# GD32F1x0 register map
File version: 1.0
CPU: CM3 r2p1, little endian, no MPU, no FPU, 4 interrupt priority bits
Registers are 32-bit, read-write, reset 0x0 unless marked. A register's access mark holds for its fields unless they carry their own. Offsets are from the block's base; [hi:lo] are bit positions; {n}, {i} and the like mark numbered series.

## I2C0 — Inter integrated circuit
Base 0x40005400
Same registers: I2C1 0x40005800, I2C2 0x4000C000
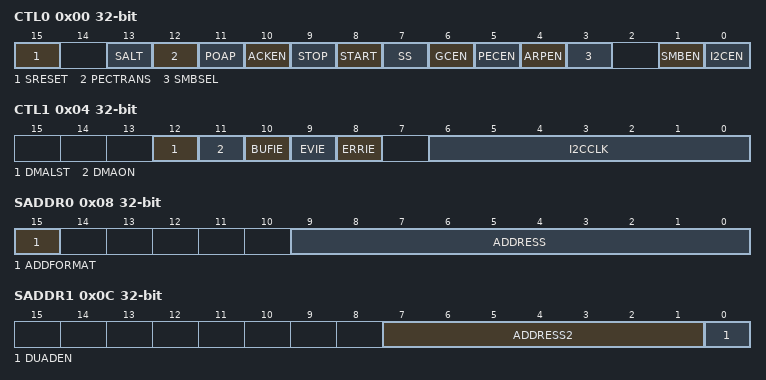
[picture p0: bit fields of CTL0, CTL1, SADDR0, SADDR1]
0x00 CTL0 — Control register 0
  [15] SRESET — Software reset I2C
  [13] SALT — SMBus alert
  [12] PECTRANS — PEC Transfer
  [11] POAP — Position of ACK meaning
  [10] ACKEN — Whether or not to send an ACK
  [9] STOP — Generate a STOP condition on I2C bus
  [8] START — Generate a START condition on I2C bus
  [7] SS — Whether to stretch SCL low when data is not ready in slave mode
  [6] GCEN — Whether or not to response to a General Call (0x00)
  [5] PECEN — PEC Calculation Switch
  [4] ARPEN — ARP protocol in SMBus switch
  [3] SMBSEL — SMBusType Selection
  [1] SMBEN — SMBus/I2C mode switch
  [0] I2CEN — I2C peripheral enable
0x04 CTL1 — Control register 1
  [12] DMALST — Flag indicating DMA last transfer
  [11] DMAON — DMA mode switch
  [10] BUFIE — Buffer interrupt enable
  [9] EVIE — Event interrupt enable
  [8] ERRIE — Error interrupt enable
  [6:0] I2CCLK — I2C Peripheral clock frequency
0x08 SADDR0 — Own address register 0
  [15] ADDFORMAT — Address mode for the I2C slave
  [9:0] ADDRESS — Interface address
0x0C SADDR1 — Own address register 1
  [7:1] ADDRESS2 — Second I2C address for the slave in Dual-Address mode
  [0] DUADEN — Dual-Address mode switch
0x10 DATA
  [7:0] TRB — Transmission or reception data buffer register
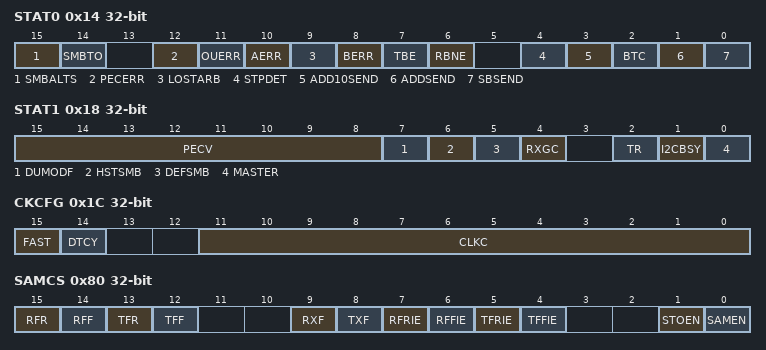
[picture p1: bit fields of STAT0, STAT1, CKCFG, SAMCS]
0x14 STAT0 access per field — Transfer status register 0
  [15] SMBALTS rw — SMBus Alert status
  [14] SMBTO rw — Timeout signal in SMBus mode
  [12] PECERR rw — PEC error when receiving data
  [11] OUERR rw — Over-run or under-run situation occurs in slave mode
  [10] AERR rw — Acknowledge error
  [9] LOSTARB rw — Arbitration Lost in master mode
  [8] BERR rw — Bus error
  [7] TBE ro — I2C_DATA is Empty during transmitting
  [6] RBNE ro — TRBR is not Empty during receiving
  [4] STPDET ro — STOP condition detected in slave mode
  [3] ADD10SEND ro — Header of 10-bit address is sent in master mode
  [2] BTC ro — Byte transmission completed
  [1] ADDSEND ro — Address is sent in master mode or received and matches in slave mode
  [0] SBSEND ro — START condition sent out in master mode
0x18 STAT1 ro — Transfer status register 1
  [15:8] PECV — Packet Error Checking Value
  [7] DUMODF — Dual Flag in slave mode
  [6] HSTSMB — SMBus Host Header detected in slave mode
  [5] DEFSMB — SMBus host header in slave mode
  [4] RXGC — General call address (00h) received
  [2] TR — Whether the I2C is a transmitter or a receiver
  [1] I2CBSY — Busy flag
  [0] MASTER — A flag indicating whether I2C block is in master or slave mode
0x1C CKCFG — Clock configure register
  [15] FAST — I2C speed selection in master mode
  [14] DTCY — Duty cycle in fast mode
  [11:0] CLKC — I2C Clock control in master mode
0x20 RT reset 0x2 — Rise time register
  [6:0] RISETIME — Maximum rise time in master mode
0x80 SAMCS — SAM Controland status register
  [15] RFR — Rxframe rise flag
  [14] RFF — Rxframe fall flag
  [13] TFR — Txframe rise flag
  [12] TFF — Txframe fall flag
  [9] RXF — Level of Rxframe signal
  [8] TXF — Level of Txframe signal
  [7] RFRIE — Rxframe rise interrupt enable
  [6] RFFIE — Rxframe fall interrupt enable
  [5] TFRIE — Txframe rise interrupt enable
  [4] TFFIE — Txframe fall interrupt enable
  [1] STOEN — SAM_V interface timeout detect enable
  [0] SAMEN — SAM_V interface enable

## NVIC — Nested Vectored Interrupt Controller
Base 0xE000E100
0x00 ISER — Interrupt Set Enable Register
  [31:0] SETENA
0x80 ICER — Interrupt Clear Enable Register
  [31:0] CLRENA
0x100 ISPR — Interrupt Set-Pending Register
  [31:0] SETPEND
0x180 ICPR — Interrupt Clear-Pending Register
  [31:0] CLRPEND
0x200 IABR — Interrupt Active bit Register
{0x300+i} IPR{i} 8-bit (i=0..73) — Interrupt Priority Register {i}
  [7:0] PRI_{i:02}
0xE00 STIR wo — Software Trigger Interrupt Register
